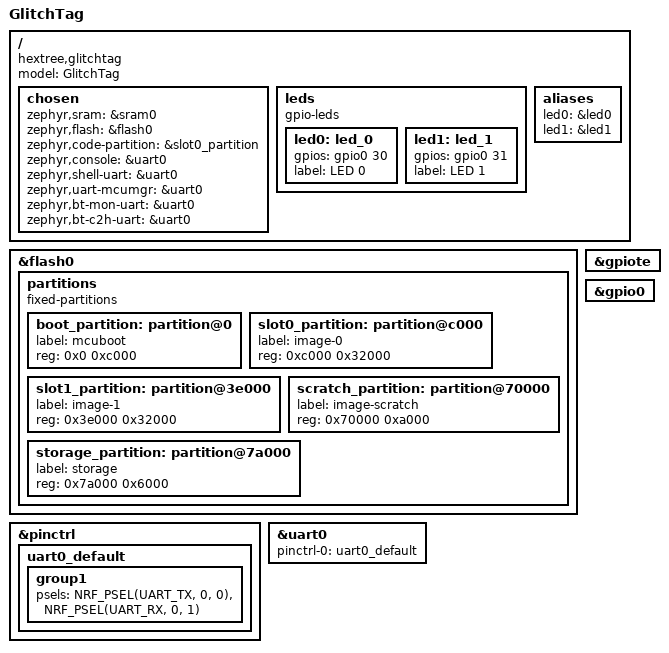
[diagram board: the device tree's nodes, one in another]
// Copyright (c) 2024 Nordic Semiconductor ASA
// SPDX-License-Identifier: Apache-2.0

/dts-v1/;
#include <nordic/nrf52832_qfaa.dtsi>

/ {
	model = "GlitchTag";
	compatible = "hextree,glitchtag";

	chosen {
		zephyr,sram = &sram0;
		zephyr,flash = &flash0;
		zephyr,code-partition = &slot0_partition;
		zephyr,console = &uart0;
		zephyr,shell-uart = &uart0;
		zephyr,uart-mcumgr = &uart0;
		zephyr,bt-mon-uart = &uart0;
		zephyr,bt-c2h-uart = &uart0;
	};

	leds {
		compatible = "gpio-leds";
		led0: led_0 {
			gpios = <&gpio0 30 GPIO_ACTIVE_HIGH>;
			label = "LED 0";
		};
		led1: led_1 {
			gpios = <&gpio0 31 GPIO_ACTIVE_HIGH>;
			label = "LED 1";
		};
	};
	/* These aliases are provided for compatibility with samples */
	aliases {
		led0 = &led0;
		led1 = &led1;
	};
};

&flash0 {
	partitions {
		compatible = "fixed-partitions";
		#address-cells = <1>;
		#size-cells = <1>;

		boot_partition: partition@0 {
			label = "mcuboot";
			reg = <0x0 0xc000>;
		};
		slot0_partition: partition@c000 {
			label = "image-0";
			reg = <0xc000 0x32000>;
		};
		slot1_partition: partition@3e000 {
			label = "image-1";
			reg = <0x3e000 0x32000>;
		};
		scratch_partition: partition@70000 {
			label = "image-scratch";
			reg = <0x70000 0xa000>;
		};
		storage_partition: partition@7a000 {
			label = "storage";
			reg = <0x7a000 0x6000>;
		};
	};
};

&gpiote {
	status = "okay";
};

&gpio0 {
	status = "okay";
};

// arduino_serial: &uart0 {
// 	status = "okay";
// 	compatible = "nordic,nrf-uarte";
// 	current-speed = <115200>;
// 	pinctrl-0 = <&uart0_default>;
	
// 	//pinctrl-1 = <&uart0_sleep>;
// 	pinctrl-names = "default", "sleep";
// };

// uart0_default: uart0_default {
// 	group1 {
// 		psels = <NRF_PSEL(UART_TX, 0, 20)>,
// 			<NRF_PSEL(UART_RX, 0, 21)>,
// 			<NRF_PSEL(UART_RTS, 0, 18)>,
// 			<NRF_PSEL(UART_CTS, 0, 16)>;
// 	};
// };
&pinctrl {

	uart0_default: uart0_default {
		group1 {
			psels = <NRF_PSEL(UART_TX, 0, 0)>, <NRF_PSEL(UART_RX, 0, 1)>;
		};
	};
};
&uart0 {
	pinctrl-0 = <&uart0_default>;
	pinctrl-names = "default";
	status = "okay";
};
